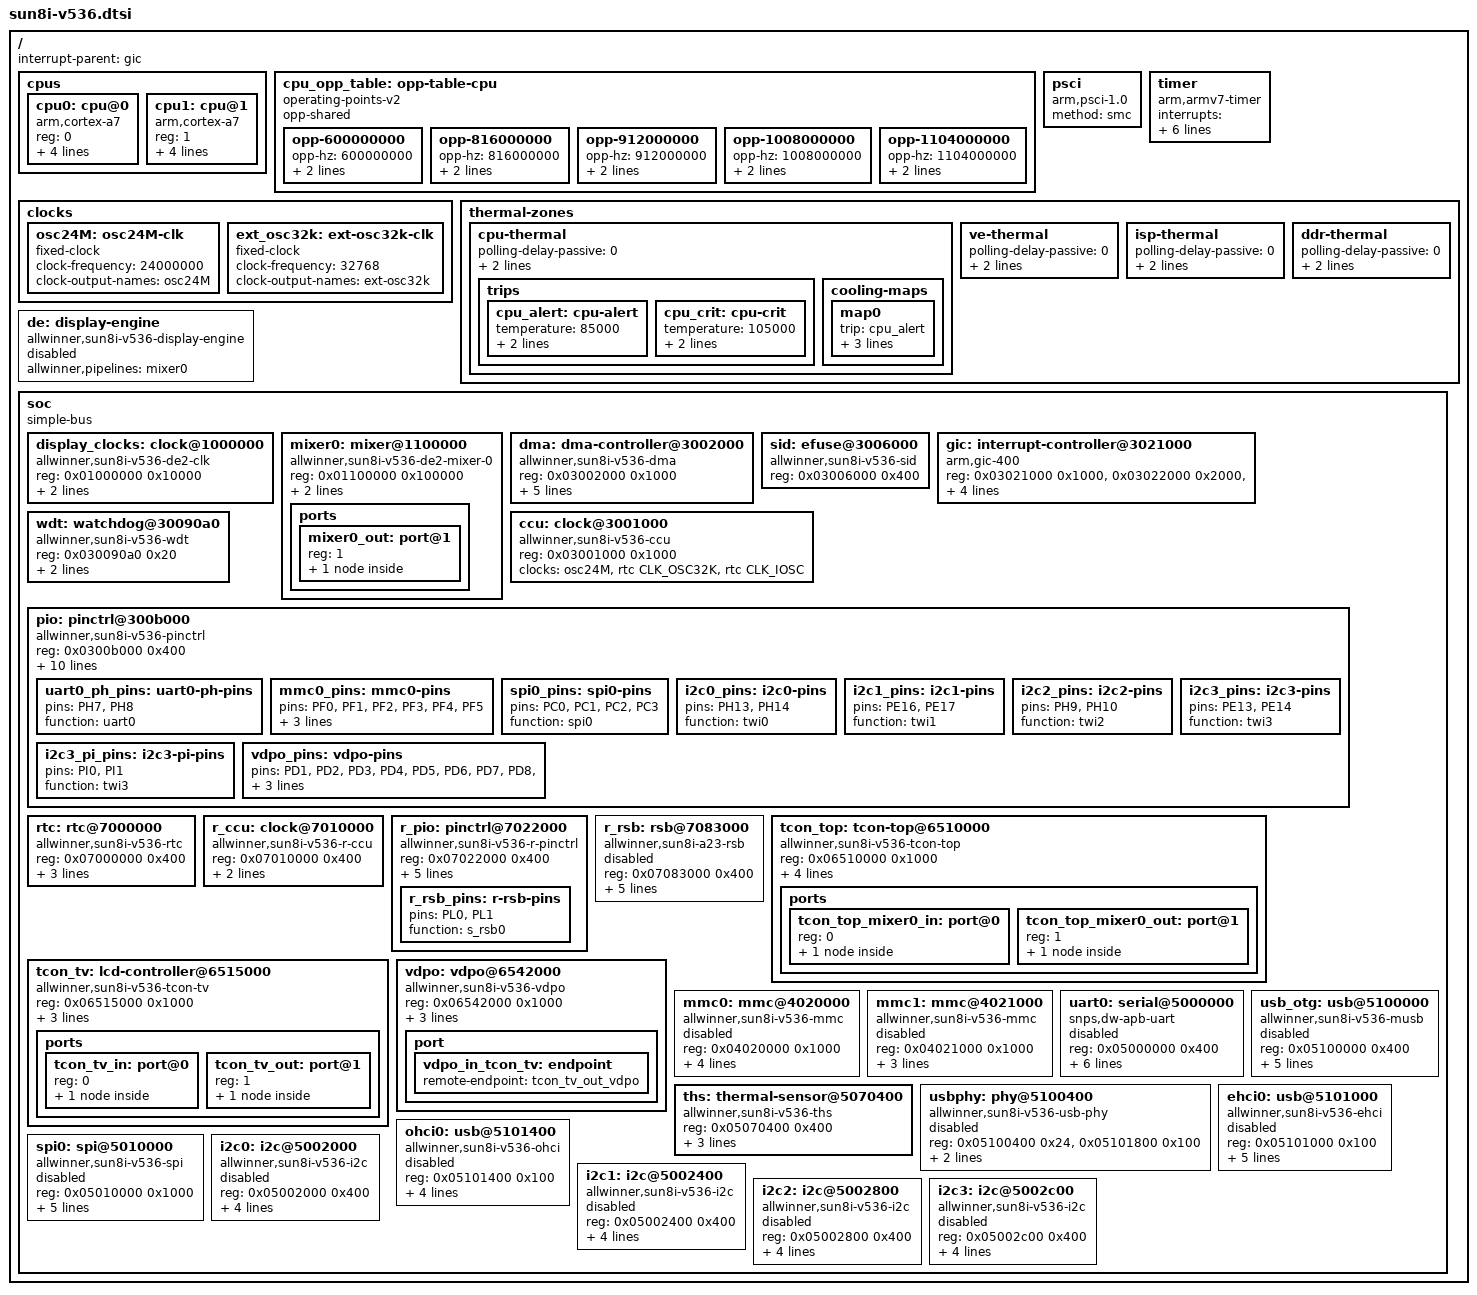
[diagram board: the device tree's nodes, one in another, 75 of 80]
// SPDX-License-Identifier: (GPL-2.0+ OR MIT)
/*
 * Allwinner V536 (sun8iw16p1) SoC devicetree.
 */

#include <dt-bindings/clock/sun6i-rtc.h>
#include <dt-bindings/clock/sun8i-v536-ccu.h>
#include <dt-bindings/thermal/thermal.h>
#include <dt-bindings/clock/sun8i-v536-r-ccu.h>
#include <dt-bindings/interrupt-controller/arm-gic.h>
#include <dt-bindings/reset/sun8i-v536-ccu.h>
#include <dt-bindings/reset/sun8i-v536-r-ccu.h>

/ {
	#address-cells = <1>;
	#size-cells = <1>;
	interrupt-parent = <&gic>;

	cpus {
		#address-cells = <1>;
		#size-cells = <0>;

		cpu0: cpu@0 {
			device_type = "cpu";
			compatible = "arm,cortex-a7";
			reg = <0>;
			enable-method = "psci";
			clocks = <&ccu CLK_CPUX>;
			clock-latency-ns = <2000000>;
			operating-points-v2 = <&cpu_opp_table>;
			#cooling-cells = <2>;
		};

		cpu1: cpu@1 {
			device_type = "cpu";
			compatible = "arm,cortex-a7";
			reg = <1>;
			enable-method = "psci";
			clocks = <&ccu CLK_CPUX>;
			clock-latency-ns = <2000000>;
			operating-points-v2 = <&cpu_opp_table>;
			#cooling-cells = <2>;
		};
	};

	cpu_opp_table: opp-table-cpu {
		compatible = "operating-points-v2";
		opp-shared;

		opp-600000000 {
			opp-hz = /bits/ 64 <600000000>;
			opp-microvolt = <820000>;
			clock-latency-ns = <2000000>;
		};

		opp-816000000 {
			opp-hz = /bits/ 64 <816000000>;
			opp-microvolt = <880000>;
			clock-latency-ns = <2000000>;
		};

		opp-912000000 {
			opp-hz = /bits/ 64 <912000000>;
			opp-microvolt = <900000>;
			clock-latency-ns = <2000000>;
		};

		opp-1008000000 {
			opp-hz = /bits/ 64 <1008000000>;
			opp-microvolt = <960000>;
			clock-latency-ns = <2000000>;
		};

		opp-1104000000 {
			opp-hz = /bits/ 64 <1104000000>;
			opp-microvolt = <1000000>;
			clock-latency-ns = <2000000>;
		};
	};

	psci {
		compatible = "arm,psci-1.0";
		method = "smc";
	};

	timer {
		compatible = "arm,armv7-timer";
		interrupts = <GIC_PPI 13 (GIC_CPU_MASK_SIMPLE(2) | IRQ_TYPE_LEVEL_LOW)>,
			     <GIC_PPI 14 (GIC_CPU_MASK_SIMPLE(2) | IRQ_TYPE_LEVEL_LOW)>,
			     <GIC_PPI 11 (GIC_CPU_MASK_SIMPLE(2) | IRQ_TYPE_LEVEL_LOW)>,
			     <GIC_PPI 10 (GIC_CPU_MASK_SIMPLE(2) | IRQ_TYPE_LEVEL_LOW)>;
		clock-frequency = <24000000>;
		arm,cpu-registers-not-fw-configured;
	};

	clocks {
		osc24M: osc24M-clk {
			compatible = "fixed-clock";
			#clock-cells = <0>;
			clock-frequency = <24000000>;
			clock-output-names = "osc24M";
		};

		ext_osc32k: ext-osc32k-clk {
			compatible = "fixed-clock";
			#clock-cells = <0>;
			clock-frequency = <32768>;
			clock-output-names = "ext-osc32k";
		};
	};

	thermal-zones {
		cpu-thermal {
			polling-delay-passive = <0>;
			polling-delay = <0>;
			thermal-sensors = <&ths 0>;

			trips {
				cpu_alert: cpu-alert {
					temperature = <85000>;
					hysteresis = <2000>;
					type = "passive";
				};

				cpu_crit: cpu-crit {
					temperature = <105000>;
					hysteresis = <2000>;
					type = "critical";
				};
			};

			cooling-maps {
				map0 {
					trip = <&cpu_alert>;
					cooling-device = <&cpu0 THERMAL_NO_LIMIT THERMAL_NO_LIMIT>,
							 <&cpu1 THERMAL_NO_LIMIT THERMAL_NO_LIMIT>;
				};
			};
		};

		ve-thermal {
			polling-delay-passive = <0>;
			polling-delay = <0>;
			thermal-sensors = <&ths 1>;
		};

		isp-thermal {
			polling-delay-passive = <0>;
			polling-delay = <0>;
			thermal-sensors = <&ths 2>;
		};

		ddr-thermal {
			polling-delay-passive = <0>;
			polling-delay = <0>;
			thermal-sensors = <&ths 3>;
		};
	};

	de: display-engine {
		compatible = "allwinner,sun8i-v536-display-engine";
		allwinner,pipelines = <&mixer0>;
		status = "disabled";
	};

	soc {
		compatible = "simple-bus";
		#address-cells = <1>;
		#size-cells = <1>;
		ranges;

		display_clocks: clock@1000000 {
			compatible = "allwinner,sun8i-v536-de2-clk",
				     "allwinner,sun8i-v3s-de2-clk";
			reg = <0x01000000 0x10000>;
			clocks = <&ccu CLK_BUS_DE>,
				 <&ccu CLK_DE>;
			clock-names = "bus",
				      "mod";
			resets = <&ccu RST_BUS_DE>;
			#clock-cells = <1>;
			#reset-cells = <1>;
		};

		mixer0: mixer@1100000 {
			compatible = "allwinner,sun8i-v536-de2-mixer-0";
			reg = <0x01100000 0x100000>;
			clocks = <&display_clocks 0>,
				 <&display_clocks 6>;
			clock-names = "bus",
				      "mod";
			resets = <&display_clocks 0>;

			ports {
				#address-cells = <1>;
				#size-cells = <0>;

				mixer0_out: port@1 {
					reg = <1>;

					mixer0_out_tcon_top_mixer0: endpoint {
						remote-endpoint = <&tcon_top_mixer0_in_mixer0>;
					};
				};
			};
		};

		dma: dma-controller@3002000 {
			compatible = "allwinner,sun8i-v536-dma",
				     "allwinner,sun50i-a100-dma";
			reg = <0x03002000 0x1000>;
			interrupts = <GIC_SPI 10 IRQ_TYPE_LEVEL_HIGH>;
			clocks = <&ccu CLK_BUS_DMA>, <&ccu CLK_MBUS_DMA>;
			clock-names = "bus", "mbus";
			resets = <&ccu RST_BUS_DMA>;
			dma-channels = <16>;
			dma-requests = <48>;
			#dma-cells = <1>;
		};

		sid: efuse@3006000 {
			compatible = "allwinner,sun8i-v536-sid";
			reg = <0x03006000 0x400>;
			#address-cells = <1>;
			#size-cells = <1>;
		};

		gic: interrupt-controller@3021000 {
			compatible = "arm,gic-400";
			reg = <0x03021000 0x1000>,
			      <0x03022000 0x2000>,
			      <0x03024000 0x2000>,
			      <0x03026000 0x2000>;
			interrupts = <GIC_PPI 9 (GIC_CPU_MASK_SIMPLE(2) | IRQ_TYPE_LEVEL_HIGH)>;
			interrupt-controller;
			#interrupt-cells = <3>;
		};

		ccu: clock@3001000 {
			compatible = "allwinner,sun8i-v536-ccu";
			reg = <0x03001000 0x1000>;
			clocks = <&osc24M>, <&rtc CLK_OSC32K>, <&rtc CLK_IOSC>;
			clock-names = "hosc", "losc", "iosc";
			#clock-cells = <1>;
			#reset-cells = <1>;
		};

		wdt: watchdog@30090a0 {
			compatible = "allwinner,sun8i-v536-wdt",
				     "allwinner,sun6i-a31-wdt";
			reg = <0x030090a0 0x20>;
			interrupts = <GIC_SPI 14 IRQ_TYPE_LEVEL_HIGH>;
			clocks = <&rtc CLK_OSC32K>;
		};

		pio: pinctrl@300b000 {
			compatible = "allwinner,sun8i-v536-pinctrl";
			reg = <0x0300b000 0x400>;
			interrupts = <GIC_SPI 67 IRQ_TYPE_LEVEL_HIGH>,
				     <GIC_SPI 68 IRQ_TYPE_LEVEL_HIGH>,
				     <GIC_SPI 69 IRQ_TYPE_LEVEL_HIGH>,
				     <GIC_SPI 70 IRQ_TYPE_LEVEL_HIGH>,
				     <GIC_SPI 71 IRQ_TYPE_LEVEL_HIGH>,
				     <GIC_SPI 72 IRQ_TYPE_LEVEL_HIGH>,
				     <GIC_SPI 73 IRQ_TYPE_LEVEL_HIGH>;
			clocks = <&ccu CLK_APB1>, <&osc24M>, <&rtc CLK_OSC32K>;
			clock-names = "apb", "hosc", "losc";
			gpio-controller;
			#gpio-cells = <3>;
			interrupt-controller;
			#interrupt-cells = <3>;

			uart0_ph_pins: uart0-ph-pins {
				pins = "PH7", "PH8";
				function = "uart0";
			};

			mmc0_pins: mmc0-pins {
				pins = "PF0", "PF1", "PF2",
				       "PF3", "PF4", "PF5";
				function = "sdc0";
				drive-strength = <30>;
				bias-pull-up;
			};

			spi0_pins: spi0-pins {
				pins = "PC0", "PC1", "PC2", "PC3";
				function = "spi0";
			};

			i2c0_pins: i2c0-pins {
				pins = "PH13", "PH14";
				function = "twi0";
			};

			i2c1_pins: i2c1-pins {
				pins = "PE16", "PE17";
				function = "twi1";
			};

			i2c2_pins: i2c2-pins {
				pins = "PH9", "PH10";
				function = "twi2";
			};

			i2c3_pins: i2c3-pins {
				pins = "PE13", "PE14";
				function = "twi3";
			};

			i2c3_pi_pins: i2c3-pi-pins {
				pins = "PI0", "PI1";
				function = "twi3";
			};

			vdpo_pins: vdpo-pins {
				pins = "PD1", "PD2", "PD3", "PD4",
				       "PD5", "PD6", "PD7", "PD8",
				       "PD10", "PD11", "PD12", "PD13",
				       "PD14", "PD15", "PD16", "PD17",
				       "PD18", "PD19", "PD20", "PD21";
				function = "vdpo0";
			};
		};

		rtc: rtc@7000000 {
			compatible = "allwinner,sun8i-v536-rtc";
			reg = <0x07000000 0x400>;
			interrupts = <GIC_SPI 107 IRQ_TYPE_LEVEL_HIGH>;
			clocks = <&ext_osc32k>;
			clock-output-names = "osc32k", "osc32k-out", "iosc";
			#clock-cells = <1>;
		};

		r_ccu: clock@7010000 {
			compatible = "allwinner,sun8i-v536-r-ccu";
			reg = <0x07010000 0x400>;
			clocks = <&osc24M>, <&rtc CLK_OSC32K>, <&rtc CLK_IOSC>,
				 <&ccu CLK_PLL_PERIPH0>;
			clock-names = "hosc", "losc", "iosc", "pll-periph";
			#clock-cells = <1>;
			#reset-cells = <1>;
		};

		r_pio: pinctrl@7022000 {
			compatible = "allwinner,sun8i-v536-r-pinctrl";
			reg = <0x07022000 0x400>;
			interrupts = <GIC_SPI 110 IRQ_TYPE_LEVEL_HIGH>;
			clocks = <&r_ccu CLK_R_APB1>, <&osc24M>, <&rtc CLK_OSC32K>;
			clock-names = "apb", "hosc", "losc";
			gpio-controller;
			#gpio-cells = <3>;
			interrupt-controller;
			#interrupt-cells = <3>;

			r_rsb_pins: r-rsb-pins {
				pins = "PL0", "PL1";
				function = "s_rsb0";
			};
		};

		r_rsb: rsb@7083000 {
			compatible = "allwinner,sun8i-a23-rsb";
			reg = <0x07083000 0x400>;
			interrupts = <GIC_SPI 114 IRQ_TYPE_LEVEL_HIGH>;
			clocks = <&r_ccu CLK_R_APB2_RSB>;
			clock-frequency = <3000000>;
			resets = <&r_ccu RST_R_APB2_RSB>;
			pinctrl-names = "default";
			pinctrl-0 = <&r_rsb_pins>;
			status = "disabled";
			#address-cells = <1>;
			#size-cells = <0>;
		};

		tcon_top: tcon-top@6510000 {
			compatible = "allwinner,sun8i-v536-tcon-top";
			reg = <0x06510000 0x1000>;
			clocks = <&ccu CLK_BUS_DISPLAY_TOP>,
				 <&ccu CLK_TCON_TV>;
			clock-names = "bus",
				      "tcon-tv0";
			clock-output-names = "tcon-top-tv0";
			resets = <&ccu RST_BUS_DISPLAY_TOP>;
			#clock-cells = <1>;

			ports {
				#address-cells = <1>;
				#size-cells = <0>;

				tcon_top_mixer0_in: port@0 {
					reg = <0>;

					tcon_top_mixer0_in_mixer0: endpoint@0 {
						reg = <0>;
						remote-endpoint = <&mixer0_out_tcon_top_mixer0>;
					};
				};

				tcon_top_mixer0_out: port@1 {
					#address-cells = <1>;
					#size-cells = <0>;
					reg = <1>;

					tcon_top_mixer0_out_tcon_tv: endpoint@2 {
						reg = <2>;
						remote-endpoint = <&tcon_tv_in_tcon_top_mixer0>;
					};
				};
			};
		};

		tcon_tv: lcd-controller@6515000 {
			compatible = "allwinner,sun8i-v536-tcon-tv";
			reg = <0x06515000 0x1000>;
			interrupts = <GIC_SPI 63 IRQ_TYPE_LEVEL_HIGH>;
			clocks = <&ccu CLK_BUS_TCON_TV>,
				 <&tcon_top 0>;
			clock-names = "ahb",
				      "tcon-ch1";
			resets = <&ccu RST_BUS_TCON_TV>;
			reset-names = "lcd";

			ports {
				#address-cells = <1>;
				#size-cells = <0>;

				tcon_tv_in: port@0 {
					reg = <0>;

					tcon_tv_in_tcon_top_mixer0: endpoint {
						remote-endpoint = <&tcon_top_mixer0_out_tcon_tv>;
					};
				};

				tcon_tv_out: port@1 {
					reg = <1>;

					tcon_tv_out_vdpo: endpoint {
						remote-endpoint = <&vdpo_in_tcon_tv>;
					};
				};
			};
		};

		vdpo: vdpo@6542000 {
			compatible = "allwinner,sun8i-v536-vdpo";
			reg = <0x06542000 0x1000>;
			interrupts = <GIC_SPI 94 IRQ_TYPE_LEVEL_HIGH>;
			clocks = <&ccu CLK_BUS_VDPO>,
				 <&ccu CLK_VDPO>;
			clock-names = "bus",
				      "mod";
			resets = <&ccu RST_BUS_VDPO>;

			port {
				vdpo_in_tcon_tv: endpoint {
					remote-endpoint = <&tcon_tv_out_vdpo>;
				};
			};
		};

		mmc0: mmc@4020000 {
			compatible = "allwinner,sun8i-v536-mmc",
				     "allwinner,sun50i-a64-mmc";
			reg = <0x04020000 0x1000>;
			interrupts = <GIC_SPI 46 IRQ_TYPE_LEVEL_HIGH>;
			clocks = <&ccu CLK_BUS_MMC0>, <&ccu CLK_MMC0>;
			clock-names = "ahb", "mmc";
			resets = <&ccu RST_BUS_MMC0>;
			reset-names = "ahb";
			pinctrl-names = "default";
			pinctrl-0 = <&mmc0_pins>;
			status = "disabled";
			#address-cells = <1>;
			#size-cells = <0>;
		};

		mmc1: mmc@4021000 {
			compatible = "allwinner,sun8i-v536-mmc",
				     "allwinner,sun50i-a64-mmc";
			reg = <0x04021000 0x1000>;
			interrupts = <GIC_SPI 47 IRQ_TYPE_LEVEL_HIGH>;
			clocks = <&ccu CLK_BUS_MMC1>, <&ccu CLK_MMC1>;
			clock-names = "ahb", "mmc";
			resets = <&ccu RST_BUS_MMC1>;
			reset-names = "ahb";
			status = "disabled";
			#address-cells = <1>;
			#size-cells = <0>;
		};

		uart0: serial@5000000 {
			compatible = "snps,dw-apb-uart";
			reg = <0x05000000 0x400>;
			interrupts = <GIC_SPI 49 IRQ_TYPE_LEVEL_HIGH>;
			reg-shift = <2>;
			reg-io-width = <4>;
			clocks = <&ccu CLK_BUS_UART0>;
			resets = <&ccu RST_BUS_UART0>;
			pinctrl-names = "default";
			pinctrl-0 = <&uart0_ph_pins>;
			status = "disabled";
		};

		ths: thermal-sensor@5070400 {
			compatible = "allwinner,sun8i-v536-ths";
			reg = <0x05070400 0x400>;
			interrupts = <GIC_SPI 1 IRQ_TYPE_LEVEL_HIGH>;
			clocks = <&ccu CLK_BUS_THS>;
			clock-names = "bus";
			resets = <&ccu RST_BUS_THS>;
			#thermal-sensor-cells = <1>;
		};

		usb_otg: usb@5100000 {
			compatible = "allwinner,sun8i-v536-musb",
				     "allwinner,sun8i-a33-musb";
			reg = <0x05100000 0x400>;
			interrupts = <GIC_SPI 64 IRQ_TYPE_LEVEL_HIGH>;
			interrupt-names = "mc";
			clocks = <&ccu CLK_BUS_OTG>;
			resets = <&ccu RST_BUS_OTG>;
			phys = <&usbphy 0>;
			phy-names = "usb";
			extcon = <&usbphy 0>;
			status = "disabled";
		};

		usbphy: phy@5100400 {
			compatible = "allwinner,sun8i-v536-usb-phy";
			reg = <0x05100400 0x24>,
			      <0x05101800 0x100>;
			reg-names = "phy_ctrl",
				    "pmu0";
			clocks = <&ccu CLK_USB_PHY0>;
			clock-names = "usb0_phy";
			resets = <&ccu RST_USB_PHY0>;
			reset-names = "usb0_reset";
			status = "disabled";
			#phy-cells = <1>;
		};

		ehci0: usb@5101000 {
			compatible = "allwinner,sun8i-v536-ehci", "generic-ehci";
			reg = <0x05101000 0x100>;
			interrupts = <GIC_SPI 65 IRQ_TYPE_LEVEL_HIGH>;
			clocks = <&ccu CLK_BUS_OHCI0>,
				 <&ccu CLK_BUS_EHCI0>,
				 <&ccu CLK_USB_OHCI0>;
			resets = <&ccu RST_BUS_OHCI0>,
				 <&ccu RST_BUS_EHCI0>;
			phys = <&usbphy 0>;
			phy-names = "usb";
			status = "disabled";
		};

		ohci0: usb@5101400 {
			compatible = "allwinner,sun8i-v536-ohci", "generic-ohci";
			reg = <0x05101400 0x100>;
			interrupts = <GIC_SPI 66 IRQ_TYPE_LEVEL_HIGH>;
			clocks = <&ccu CLK_BUS_OHCI0>,
				 <&ccu CLK_USB_OHCI0>;
			resets = <&ccu RST_BUS_OHCI0>;
			phys = <&usbphy 0>;
			phy-names = "usb";
			status = "disabled";
		};

		spi0: spi@5010000 {
			compatible = "allwinner,sun8i-v536-spi",
				     "allwinner,sun8i-h3-spi";
			reg = <0x05010000 0x1000>;
			interrupts = <GIC_SPI 54 IRQ_TYPE_LEVEL_HIGH>;
			clocks = <&ccu CLK_BUS_SPI0>, <&ccu CLK_SPI0>;
			clock-names = "ahb", "mod";
			resets = <&ccu RST_BUS_SPI0>;
			dmas = <&dma 22>, <&dma 22>;
			dma-names = "rx", "tx";
			pinctrl-names = "default";
			pinctrl-0 = <&spi0_pins>;
			status = "disabled";
			#address-cells = <1>;
			#size-cells = <0>;
		};

		i2c0: i2c@5002000 {
			compatible = "allwinner,sun8i-v536-i2c",
				     "allwinner,sun6i-a31-i2c";
			reg = <0x05002000 0x400>;
			interrupts = <GIC_SPI 41 IRQ_TYPE_LEVEL_HIGH>;
			clocks = <&ccu CLK_BUS_I2C0>;
			resets = <&ccu RST_BUS_I2C0>;
			pinctrl-names = "default";
			pinctrl-0 = <&i2c0_pins>;
			status = "disabled";
			#address-cells = <1>;
			#size-cells = <0>;
		};

		i2c1: i2c@5002400 {
			compatible = "allwinner,sun8i-v536-i2c",
				     "allwinner,sun6i-a31-i2c";
			reg = <0x05002400 0x400>;
			interrupts = <GIC_SPI 42 IRQ_TYPE_LEVEL_HIGH>;
			clocks = <&ccu CLK_BUS_I2C1>;
			resets = <&ccu RST_BUS_I2C1>;
			pinctrl-names = "default";
			pinctrl-0 = <&i2c1_pins>;
			status = "disabled";
			#address-cells = <1>;
			#size-cells = <0>;
		};

		i2c2: i2c@5002800 {
			compatible = "allwinner,sun8i-v536-i2c",
				     "allwinner,sun6i-a31-i2c";
			reg = <0x05002800 0x400>;
			interrupts = <GIC_SPI 43 IRQ_TYPE_LEVEL_HIGH>;
			clocks = <&ccu CLK_BUS_I2C2>;
			resets = <&ccu RST_BUS_I2C2>;
			pinctrl-names = "default";
			pinctrl-0 = <&i2c2_pins>;
			status = "disabled";
			#address-cells = <1>;
			#size-cells = <0>;
		};

		i2c3: i2c@5002c00 {
			compatible = "allwinner,sun8i-v536-i2c",
				     "allwinner,sun6i-a31-i2c";
			reg = <0x05002c00 0x400>;
			interrupts = <GIC_SPI 44 IRQ_TYPE_LEVEL_HIGH>;
			clocks = <&ccu CLK_BUS_I2C3>;
			resets = <&ccu RST_BUS_I2C3>;
			pinctrl-names = "default";
			pinctrl-0 = <&i2c3_pins>;
			status = "disabled";
			#address-cells = <1>;
			#size-cells = <0>;
		};
	};
};
